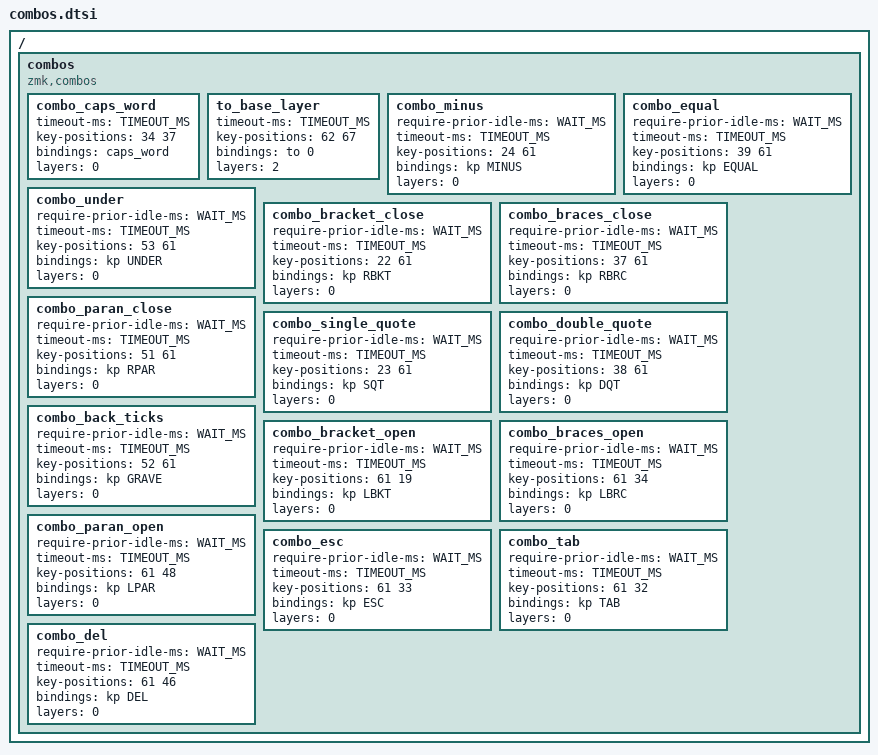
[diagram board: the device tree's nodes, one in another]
#define TIMEOUT_MS 50
#define WAIT_MS 180

/ { 
    combos {

        compatible = "zmk,combos";

        combo_caps_word {
            timeout-ms = <TIMEOUT_MS>;
            key-positions = <34 37>;
            bindings = <&caps_word>;   
            layers = <0>;
        };

        to_base_layer {
            timeout-ms = <TIMEOUT_MS>;
            key-positions = <62 67>;
            bindings = <&to 0>;   
            layers = <2>;
        };


       combo_minus {
            require-prior-idle-ms = <WAIT_MS>;
            timeout-ms = <TIMEOUT_MS>;
            key-positions = <24 61>;
            bindings = <&kp MINUS>;
            layers = <0>;
        };

        combo_equal {
            require-prior-idle-ms = <WAIT_MS>;
            timeout-ms = <TIMEOUT_MS>;
            key-positions = <39 61>;
            bindings = <&kp EQUAL>;
            layers = <0>;
        };

        combo_under {
            require-prior-idle-ms = <WAIT_MS>;
            timeout-ms = <TIMEOUT_MS>;
            key-positions = <53 61>;
            bindings = <&kp UNDER>;
            layers = <0>;
       };

        combo_bracket_close {
            require-prior-idle-ms = <WAIT_MS>;
            timeout-ms = <TIMEOUT_MS>;
            key-positions = <22 61>;
            bindings = <&kp RBKT>;
            layers = <0>;
        };

        combo_braces_close {
            require-prior-idle-ms = <WAIT_MS>;
            timeout-ms = <TIMEOUT_MS>;
            key-positions = <37 61>;
            bindings = <&kp RBRC>;
            layers = <0>;
        };

        combo_paran_close {
            require-prior-idle-ms = <WAIT_MS>;
            timeout-ms = <TIMEOUT_MS>;
            key-positions = <51 61>;
            bindings = <&kp RPAR>;
            layers = <0>;
        };   

       combo_single_quote {
            require-prior-idle-ms = <WAIT_MS>;
            timeout-ms = <TIMEOUT_MS>;
            key-positions = <23 61>;
            bindings = <&kp SQT>;
            layers = <0>;
        };

        combo_double_quote {
            require-prior-idle-ms = <WAIT_MS>;
            timeout-ms = <TIMEOUT_MS>;
            key-positions = <38 61>;
            bindings = <&kp DQT>;
            layers = <0>;
        };    

        combo_back_ticks {
            require-prior-idle-ms = <WAIT_MS>;
            timeout-ms = <TIMEOUT_MS>;
            key-positions = <52 61>;
            bindings = <&kp GRAVE>;
            layers = <0>;
        };   

        combo_bracket_open {
            require-prior-idle-ms = <WAIT_MS>;
            timeout-ms = <TIMEOUT_MS>;
            key-positions = <61 19>;
            bindings = <&kp LBKT>;
            layers = <0>;
        };

        combo_braces_open {
            require-prior-idle-ms = <WAIT_MS>;
            timeout-ms = <TIMEOUT_MS>;
            key-positions = <61 34>;
            bindings = <&kp LBRC>;
            layers = <0>;
        };
 
        combo_paran_open {
            require-prior-idle-ms = <WAIT_MS>;
            timeout-ms = <TIMEOUT_MS>;
            key-positions = <61 48>;
            bindings = <&kp LPAR>;
            layers = <0>;
        };    

        combo_esc {
            require-prior-idle-ms = <WAIT_MS>;
            timeout-ms = <TIMEOUT_MS>;
            key-positions = <61 33>;
            bindings = <&kp ESC>;
            layers = <0>;
        };

        combo_tab {
            require-prior-idle-ms = <WAIT_MS>;
            timeout-ms = <TIMEOUT_MS>;
            key-positions = <61 32>;
            bindings = <&kp TAB>;
            layers = <0>;
        };    

        combo_del {
            require-prior-idle-ms = <WAIT_MS>;
            timeout-ms = <TIMEOUT_MS>;
            key-positions = <61 46>;
            bindings = <&kp DEL>;
            layers = <0>;
        };    
    };
};
